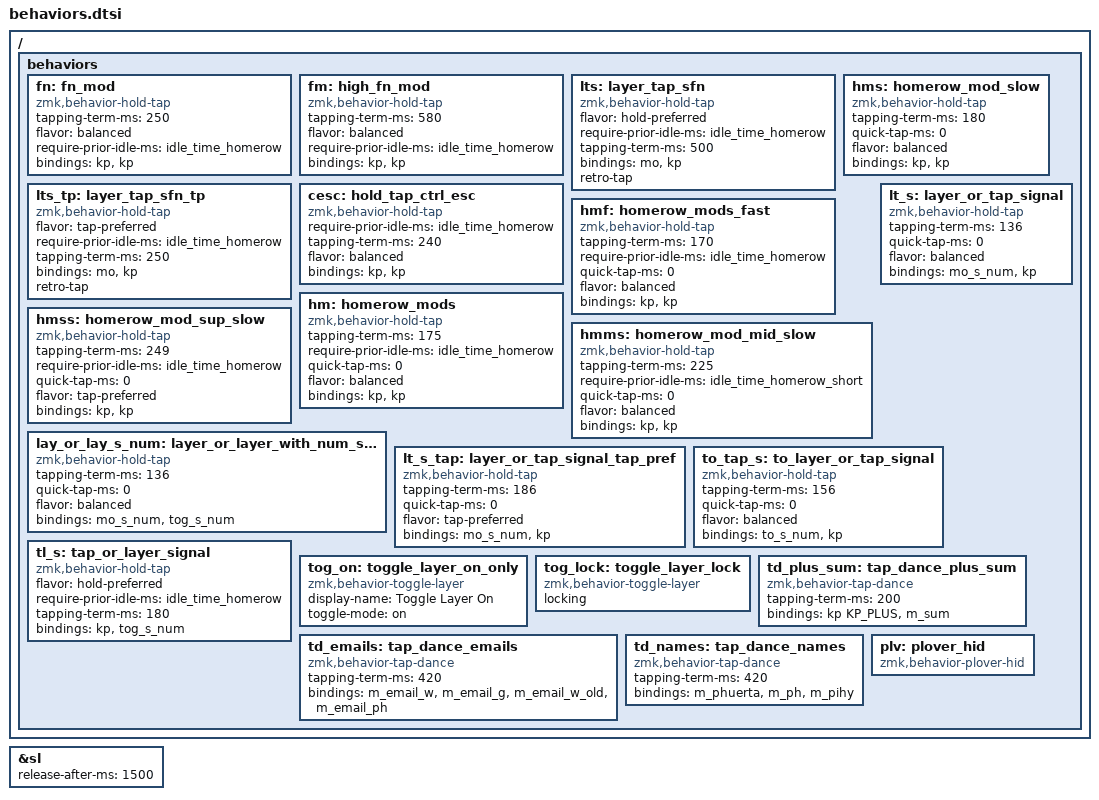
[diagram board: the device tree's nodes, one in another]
/* Global sticky-layer timeout (applies to all &sl bindings). */
&sl {
	release-after-ms = <1500>;
};

#define idle_time_homerow 120
#define idle_time_homerow_short 70

/ { behaviors {
	/* ── Mod / layer hold-taps ─────────────────────────────────────────── */

	fn: fn_mod {
		compatible = "zmk,behavior-hold-tap";
		tapping-term-ms = <250>;
		flavor = "balanced";
		require-prior-idle-ms = <idle_time_homerow>;
		#binding-cells = <2>;
		bindings = <&kp>, <&kp>;
	};

	fm: high_fn_mod {
		compatible = "zmk,behavior-hold-tap";
		tapping-term-ms = <580>;
		flavor = "balanced";
		require-prior-idle-ms = <idle_time_homerow>;
		#binding-cells = <2>;
		bindings = <&kp>, <&kp>;
	};

	lts: layer_tap_sfn {
		compatible = "zmk,behavior-hold-tap";
		#binding-cells = <2>;
		flavor = "hold-preferred";
		require-prior-idle-ms = <idle_time_homerow>;
		tapping-term-ms = <500>;
		bindings = <&mo>, <&kp>;
		retro-tap;
	};

	lts_tp: layer_tap_sfn_tp {
		compatible = "zmk,behavior-hold-tap";
		#binding-cells = <2>;
		flavor = "tap-preferred";
		require-prior-idle-ms = <idle_time_homerow>;
		tapping-term-ms = <250>;
		bindings = <&mo>, <&kp>;
		retro-tap;
	};

	cesc: hold_tap_ctrl_esc {
		compatible = "zmk,behavior-hold-tap";
		#binding-cells = <2>;
		require-prior-idle-ms = <idle_time_homerow>;
		tapping-term-ms = <240>;
		flavor = "balanced";
		bindings = <&kp>, <&kp>;
	};

	/* ── Homerow mods (tapping-term / idle tuning) ───────────────────────── */

	hmf: homerow_mods_fast {
		compatible = "zmk,behavior-hold-tap";
		#binding-cells = <2>;
		tapping-term-ms = <170>;
		require-prior-idle-ms = <idle_time_homerow>;
		quick-tap-ms = <0>;
		flavor = "balanced";
		bindings = <&kp>, <&kp>;
	};

	hm: homerow_mods {
		compatible = "zmk,behavior-hold-tap";
		#binding-cells = <2>;
		tapping-term-ms = <175>;
		require-prior-idle-ms = <idle_time_homerow>;
		quick-tap-ms = <0>;
		flavor = "balanced";
		bindings = <&kp>, <&kp>;
	};

	hms: homerow_mod_slow {
		compatible = "zmk,behavior-hold-tap";
		#binding-cells = <2>;
		tapping-term-ms = <180>;
		quick-tap-ms = <0>;
		flavor = "balanced";
		bindings = <&kp>, <&kp>;
	};

	hmms: homerow_mod_mid_slow {
		compatible = "zmk,behavior-hold-tap";
		#binding-cells = <2>;
		tapping-term-ms = <225>;
		require-prior-idle-ms = <idle_time_homerow_short>;
		quick-tap-ms = <0>;
		flavor = "balanced";
		bindings = <&kp>, <&kp>;
	};

	hmss: homerow_mod_sup_slow {
		compatible = "zmk,behavior-hold-tap";
		#binding-cells = <2>;
		tapping-term-ms = <249>;
		require-prior-idle-ms = <idle_time_homerow>;
		quick-tap-ms = <0>;
		flavor = "tap-preferred";
		bindings = <&kp>, <&kp>;
	};

	/* ── Numpad F18 signal wrappers (see macros.dtsi to_s_num / mo_s_num) ─ */

	lay_or_lay_s_num: layer_or_layer_with_num_signal {
		compatible = "zmk,behavior-hold-tap";
		#binding-cells = <2>;
		tapping-term-ms = <136>;
		quick-tap-ms = <0>;
		flavor = "balanced";
		bindings = <&mo_s_num>, <&tog_s_num>;
	};

	lt_s: layer_or_tap_signal {
		compatible = "zmk,behavior-hold-tap";
		#binding-cells = <2>;
		tapping-term-ms = <136>;
		quick-tap-ms = <0>;
		flavor = "balanced";
		bindings = <&mo_s_num>, <&kp>;
	};

	lt_s_tap: layer_or_tap_signal_tap_pref {
		compatible = "zmk,behavior-hold-tap";
		#binding-cells = <2>;
		tapping-term-ms = <186>;
		quick-tap-ms = <0>;
		flavor = "tap-preferred";
		bindings = <&mo_s_num>, <&kp>;
	};

	to_tap_s: to_layer_or_tap_signal {
		compatible = "zmk,behavior-hold-tap";
		#binding-cells = <2>;
		tapping-term-ms = <156>;
		quick-tap-ms = <0>;
		flavor = "balanced";
		bindings = <&to_s_num>, <&kp>;
	};

	tl_s: tap_or_layer_signal {
		compatible = "zmk,behavior-hold-tap";
		#binding-cells = <2>;
		flavor = "hold-preferred";
		require-prior-idle-ms = <idle_time_homerow>;
		tapping-term-ms = <180>;
		bindings = <&kp>, <&tog_s_num>;
	};

	tog_on: toggle_layer_on_only {
		compatible = "zmk,behavior-toggle-layer";
		#binding-cells = <1>;
		display-name = "Toggle Layer On";
		toggle-mode = "on";
	};

	tog_lock: toggle_layer_lock {
		compatible = "zmk,behavior-toggle-layer";
		#binding-cells = <1>;
		locking;
	};

	/* ── Tap dances ────────────────────────────────────────────────────── */

	td_plus_sum: tap_dance_plus_sum {
		compatible = "zmk,behavior-tap-dance";
		#binding-cells = <0>;
		tapping-term-ms = <200>;
		bindings = <&kp KP_PLUS>, <&m_sum>;
	};

	td_emails: tap_dance_emails {
		compatible = "zmk,behavior-tap-dance";
		#binding-cells = <0>;
		tapping-term-ms = <420>;
		bindings = <&m_email_w>, <&m_email_g>, <&m_email_w_old>, <&m_email_ph>;
	};

	td_names: tap_dance_names {
		compatible = "zmk,behavior-tap-dance";
		#binding-cells = <0>;
		tapping-term-ms = <420>;
		bindings = <&m_phuerta>, <&m_ph>, <&m_pihy>;
	};

	/* ── Plover HID ────────────────────────────────────────────────────── */

	plv: plover_hid {
		compatible = "zmk,behavior-plover-hid";
		#binding-cells = <1>;
	};
}; };
